AUTOSAR XML (schema 00046)
package /ComponentTypes
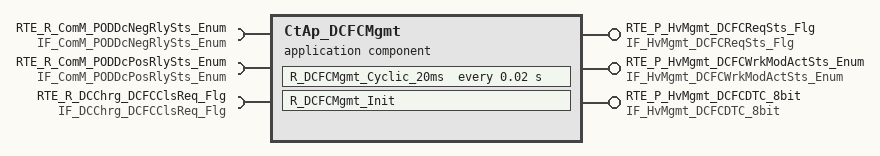
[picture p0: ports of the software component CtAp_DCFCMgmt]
  application sw component type CtAp_DCFCMgmt
    provide port RTE_P_HvMgmt_DCFCReqSts_Flg: nonqueued-sender-com-spec{data-element=tec_HvMgmt_DCFCReqSts_Flg, init-value=0}, provided-interface=IF_HvMgmt_DCFCReqSts_Flg
    provide port RTE_P_HvMgmt_DCFCWrkModActSts_Enum: nonqueued-sender-com-spec{data-element=tec_HvMgmt_DCFCWrkModActSts_Enum, init-value=0}, provided-interface=IF_HvMgmt_DCFCWrkModActSts_Enum
    provide port RTE_P_HvMgmt_DCFCDTC_8bit: nonqueued-sender-com-spec{data-element=tec_HvMgmt_DCFCDTC_8bit, init-value=0}, provided-interface=IF_HvMgmt_DCFCDTC_8bit
    require port RTE_R_ComM_PODDcNegRlySts_Enum: nonqueued-receiver-com-spec{data-element=tec_ComM_PODDcNegRlySts_Enum, filter=data-filter-type=ALWAYS, init-value=0}, required-interface=IF_ComM_PODDcNegRlySts_Enum
    require port RTE_R_ComM_PODDcPosRlySts_Enum: nonqueued-receiver-com-spec{data-element=tec_ComM_PODDcPosRlySts_Enum, filter=data-filter-type=ALWAYS, init-value=0}, required-interface=IF_ComM_PODDcPosRlySts_Enum
    require port RTE_R_DCChrg_DCFCClsReq_Flg: nonqueued-receiver-com-spec{data-element=tec_DCChrg_DCFCClsReq_Flg, filter=data-filter-type=ALWAYS, init-value=0}, required-interface=IF_DCChrg_DCFCClsReq_Flg
    behavior CtAp_DCFCMgmt_InternalBehavior
      init event CtAp_DCFCMgmt_InitEvent: start-on-event=R_DCFCMgmt_Init
      timing event TMT_R_DCFCMgmt_Cyclic_20ms: start-on-event=R_DCFCMgmt_Cyclic_20ms, period=0.02
      runnable R_DCFCMgmt_Init
      runnable R_DCFCMgmt_Cyclic_20ms
        data-receive-point-by-arguments:
          access REC_RTE_R_ComM_PODDcNegRlySts_Enum_tec_ComM_PODDcNegRlySts_Enum: accessed-variable=RTE_R_ComM_PODDcNegRlySts_Enum.tec_ComM_PODDcNegRlySts_Enum
          access REC_RTE_R_ComM_PODDcPosRlySts_Enum_tec_ComM_PODDcPosRlySts_Enum: accessed-variable=RTE_R_ComM_PODDcPosRlySts_Enum.tec_ComM_PODDcPosRlySts_Enum
          access REC_RTE_R_DCChrg_DCFCClsReq_Flg_tec_DCChrg_DCFCClsReq_Flg: accessed-variable=RTE_R_DCChrg_DCFCClsReq_Flg.tec_DCChrg_DCFCClsReq_Flg
        data-send-points:
          access SEND_RTE_P_HvMgmt_DCFCDTC_8bit_tec_HvMgmt_DCFCDTC_8bit: accessed-variable=RTE_P_HvMgmt_DCFCDTC_8bit.tec_HvMgmt_DCFCDTC_8bit
          access SEND_RTE_P_HvMgmt_DCFCReqSts_Flg_tec_HvMgmt_DCFCReqSts_Flg: accessed-variable=RTE_P_HvMgmt_DCFCReqSts_Flg.tec_HvMgmt_DCFCReqSts_Flg
          access SEND_RTE_P_HvMgmt_DCFCWrkModActSts_Enum_tec_HvMgmt_DCFCWrkModActSts_Enum: accessed-variable=RTE_P_HvMgmt_DCFCWrkModActSts_Enum.tec_HvMgmt_DCFCWrkModActSts_Enum
  swc implementation CtAp_DCFCMgmt_Implementation: behavior=CtAp_DCFCMgmt_InternalBehavior
    code-descriptors:
      code Default: artifact-descriptors=autosar-engineering-object=category=SWOBJ
